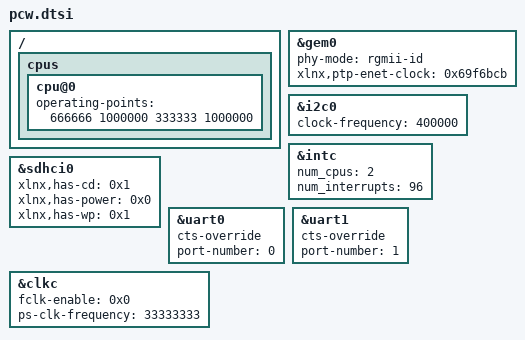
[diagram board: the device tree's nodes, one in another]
/*
 * CAUTION: This file is automatically generated by Xilinx.
 * Version:
 * Today is: Tue Jan 10 17:21:25 2023
 */


/ {
	cpus {
		cpu@0 {
			operating-points = <666666 1000000 333333 1000000>;
		};
	};
};
&gem0 {
	phy-mode = "rgmii-id";
	status = "okay";
	xlnx,ptp-enet-clock = <0x69f6bcb>;
};
&i2c0 {
	clock-frequency = <400000>;
	status = "okay";
};
&intc {
	num_cpus = <2>;
	num_interrupts = <96>;
};
&sdhci0 {
	status = "okay";
	xlnx,has-cd = <0x1>;
	xlnx,has-power = <0x0>;
	xlnx,has-wp = <0x1>;
};
&uart0 {
	cts-override ;
	device_type = "serial";
	port-number = <0>;
	status = "okay";
};
&uart1 {
	cts-override ;
	device_type = "serial";
	port-number = <1>;
	status = "okay";
};
/*&usb0 {
	phy_type = "ulpi";
	status = "okay";
	usb-reset = <&gpio0 48 0>;
};*/
&clkc {
	fclk-enable = <0x0>;
	ps-clk-frequency = <33333333>;
};
